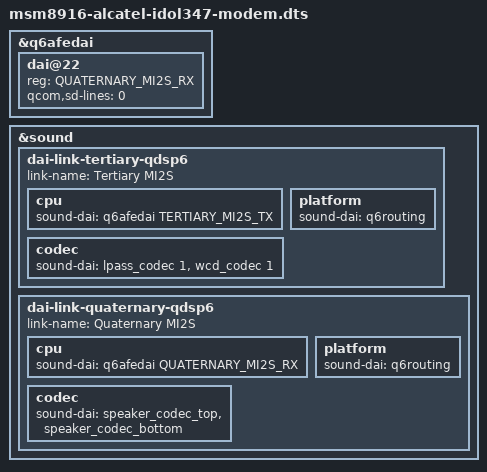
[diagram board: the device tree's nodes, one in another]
// SPDX-License-Identifier: GPL-2.0-only
#include "msm8916-alcatel-idol347.dts"
#include "msm8916-modem.dtsi"

&q6afedai {
	dai@22 {
		reg = <QUATERNARY_MI2S_RX>;
		qcom,sd-lines = <0>;
	};
};

&sound {
	/delete-node/ dai-link-primary;
	/delete-node/ dai-link-tertiary;
	/delete-node/ dai-link-quaternary;

	dai-link-tertiary-qdsp6 {
		link-name = "Tertiary MI2S";
		cpu {
			sound-dai = <&q6afedai TERTIARY_MI2S_TX>;
		};
		platform {
			sound-dai = <&q6routing>;
		};
		codec {
			sound-dai = <&lpass_codec 1>, <&wcd_codec 1>;
		};
	};

	dai-link-quaternary-qdsp6 {
		link-name = "Quaternary MI2S";
		cpu {
			sound-dai = <&q6afedai QUATERNARY_MI2S_RX>;
		};
		platform {
			sound-dai = <&q6routing>;
		};
		codec {
			sound-dai = <&speaker_codec_top>, <&speaker_codec_bottom>;
		};
	};
};
